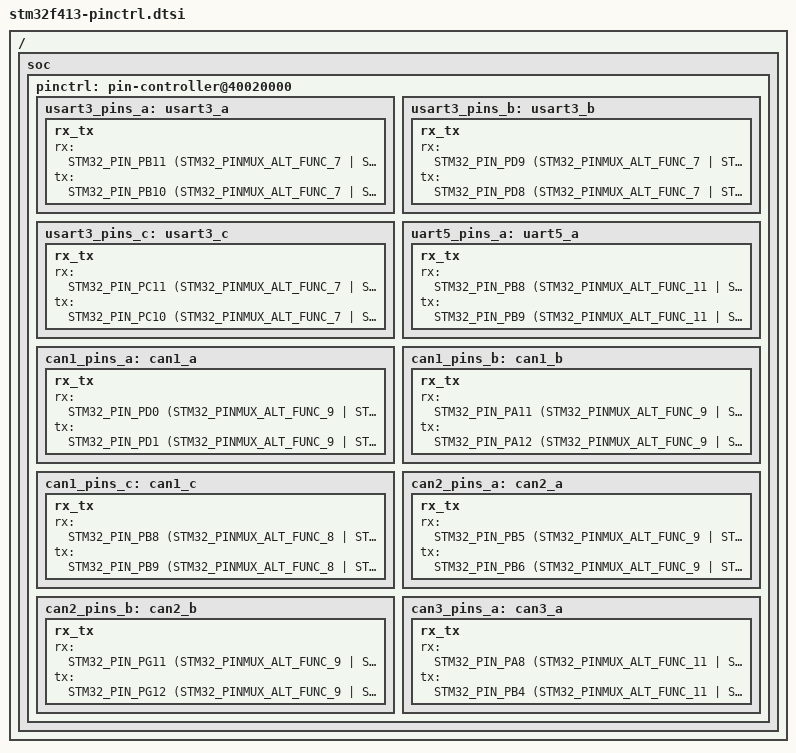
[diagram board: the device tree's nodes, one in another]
/*
 * Copyright (c) 2017 Florian Vaussard, HEIG-VD
 *
 * SPDX-License-Identifier: Apache-2.0
 */

#include <dt-bindings/pinctrl/stm32-pinctrl.h>

/ {
	soc {
		pinctrl: pin-controller@40020000 {
			usart3_pins_a: usart3_a {
				rx_tx {
					rx = <STM32_PIN_PB11 (STM32_PINMUX_ALT_FUNC_7 | STM32_PUSHPULL_PULLUP)>;
					tx = <STM32_PIN_PB10 (STM32_PINMUX_ALT_FUNC_7 | STM32_PUSHPULL_PULLUP)>;
				};
			};
			usart3_pins_b: usart3_b {
				rx_tx {
					rx = <STM32_PIN_PD9 (STM32_PINMUX_ALT_FUNC_7 | STM32_PUSHPULL_PULLUP)>;
					tx = <STM32_PIN_PD8 (STM32_PINMUX_ALT_FUNC_7 | STM32_PUSHPULL_PULLUP)>;
				};
			};
			usart3_pins_c: usart3_c {
				rx_tx {
					rx = <STM32_PIN_PC11 (STM32_PINMUX_ALT_FUNC_7 | STM32_PUSHPULL_PULLUP)>;
					tx = <STM32_PIN_PC10 (STM32_PINMUX_ALT_FUNC_7 | STM32_PUSHPULL_PULLUP)>;
				};
			};
			uart5_pins_a: uart5_a {
				rx_tx {
					rx = <STM32_PIN_PB8 (STM32_PINMUX_ALT_FUNC_11 | STM32_PUSHPULL_PULLUP)>;
					tx = <STM32_PIN_PB9 (STM32_PINMUX_ALT_FUNC_11 | STM32_PUSHPULL_PULLUP)>;
				};
			};
			can1_pins_a: can1_a {
				rx_tx {
					rx = <STM32_PIN_PD0 (STM32_PINMUX_ALT_FUNC_9 | STM32_PUPDR_PULL_UP)>;
					tx = <STM32_PIN_PD1 (STM32_PINMUX_ALT_FUNC_9 | STM32_PUPDR_NO_PULL)>;
				};
			};
			can1_pins_b: can1_b {
				rx_tx {
					rx = <STM32_PIN_PA11 (STM32_PINMUX_ALT_FUNC_9 | STM32_PUPDR_PULL_UP)>;
					tx = <STM32_PIN_PA12 (STM32_PINMUX_ALT_FUNC_9 | STM32_PUPDR_NO_PULL)>;
				};
			};
			can1_pins_c: can1_c {
				rx_tx {
					rx = <STM32_PIN_PB8 (STM32_PINMUX_ALT_FUNC_8 | STM32_PUPDR_PULL_UP)>;
					tx = <STM32_PIN_PB9 (STM32_PINMUX_ALT_FUNC_8 | STM32_PUPDR_NO_PULL)>;
				};
			};
			can2_pins_a: can2_a {
				rx_tx {
					rx = <STM32_PIN_PB5 (STM32_PINMUX_ALT_FUNC_9 | STM32_PUPDR_PULL_UP)>;
					tx = <STM32_PIN_PB6 (STM32_PINMUX_ALT_FUNC_9 | STM32_PUPDR_NO_PULL)>;
				};
			};
			can2_pins_b: can2_b {
				rx_tx {
					rx = <STM32_PIN_PG11 (STM32_PINMUX_ALT_FUNC_9 | STM32_PUPDR_PULL_UP)>;
					tx = <STM32_PIN_PG12 (STM32_PINMUX_ALT_FUNC_9 | STM32_PUPDR_NO_PULL)>;
				};
			};
			can3_pins_a: can3_a {
				rx_tx {
					rx = <STM32_PIN_PA8 (STM32_PINMUX_ALT_FUNC_11 | STM32_PUPDR_PULL_UP)>;
					tx = <STM32_PIN_PB4 (STM32_PINMUX_ALT_FUNC_11 | STM32_PUPDR_NO_PULL)>;
				};
			};
		};
	};
};
